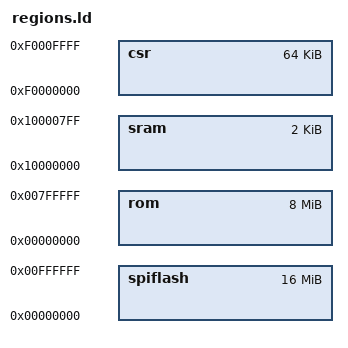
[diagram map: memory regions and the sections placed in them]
MEMORY {
	sram : ORIGIN = 0x10000000, LENGTH = 0x00000800
	spiflash : ORIGIN = 0x00000000, LENGTH = 0x01000000
	rom : ORIGIN = 0x00000000, LENGTH = 0x00800000
	csr : ORIGIN = 0xf0000000, LENGTH = 0x00010000
}
